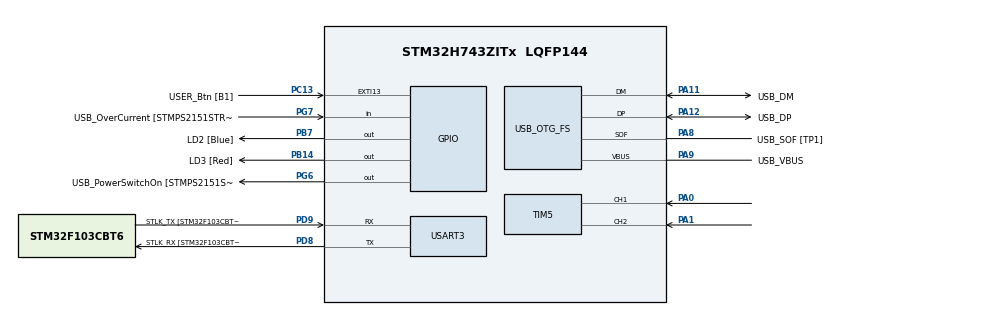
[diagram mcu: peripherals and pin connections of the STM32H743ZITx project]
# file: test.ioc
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Mcu.Family=STM32H7
Mcu.Name=STM32H743ZITx
Mcu.Package=LQFP144
NVIC.PriorityGroup=NVIC_PRIORITYGROUP_4
PA0.Signal=S_TIM5_CH1
PA1.Signal=S_TIM5_CH2
PA10.GPIO_Label=USB_ID
PA10.Signal=USB_OTG_FS_ID
PA11.GPIO_Label=USB_DM
PA11.Mode=Device_Only
PA11.Signal=USB_OTG_FS_DM
PA12.GPIO_Label=USB_DP
PA12.Mode=Device_Only
PA12.Signal=USB_OTG_FS_DP
PA2.GPIO_Label=RMII_MDIO
PA2.Signal=ETH_MDIO
PA7.GPIO_Label=RMII_CRS_DV
PA7.Signal=ETH_CRS_DV
PA8.GPIO_Label=USB_SOF [TP1]
PA8.Mode=Activate_SOF_FS
PA8.Signal=USB_OTG_FS_SOF
PA9.GPIO_Label=USB_VBUS
PA9.Mode=Activate_VBUS
PA9.Signal=USB_OTG_FS_VBUS
PB13.GPIO_Label=RMII_TXD1
PB13.Signal=ETH_TXD1
PB14.GPIO_Label=LD3 [Red]
PB14.Signal=GPIO_Output
PB7.GPIO_Label=LD2 [Blue]
PB7.Signal=GPIO_Output
PC1.GPIO_Label=RMII_MDC
PC1.Signal=ETH_MDC
PC13.GPIO_Label=USER_Btn [B1]
PC13.Signal=GPXTI13
PC14-OSC32_IN\ (OSC32_IN).Mode=LSE-External-Oscillator
PC14-OSC32_IN\ (OSC32_IN).Signal=RCC_OSC32_IN
PC15-OSC32_OUT\ (OSC32_OUT).Mode=LSE-External-Oscillator
PC15-OSC32_OUT\ (OSC32_OUT).Signal=RCC_OSC32_OUT
PC4.GPIO_Label=RMII_RXD0
PC4.Signal=ETH_RXD0
PC5.GPIO_Label=RMII_RXD1
PC5.Signal=ETH_RXD1
PD8.GPIO_Label=STLK_RX [STM32F103CBT6_PA3]
PD8.Mode=Asynchronous
PD8.Signal=USART3_TX
PD9.GPIO_Label=STLK_TX [STM32F103CBT6_PA2]
PD9.Mode=Asynchronous
PD9.Signal=USART3_RX
PG11.GPIO_Label=RMII_TX_EN
PG11.Signal=ETH_TX_EN
PG13.GPIO_Label=RMII_TXD0
PG13.Signal=ETH_TXD0
PG6.GPIO_Label=USB_PowerSwitchOn [STMPS2151STR_EN]
PG6.Signal=GPIO_Output
PG7.GPIO_Label=USB_OverCurrent [STMPS2151STR_FAULT]
PG7.Signal=GPIO_Input
PH0-OSC_IN\ (PH0).GPIO_Label=MCO
PH0-OSC_IN\ (PH0).Mode=HSE-External-Clock-Source
PH0-OSC_IN\ (PH0).Signal=RCC_OSC_IN
PH1-OSC_OUT\ (PH1).Signal=RCC_OSC_OUT
ProjectManager.HeapSize=0x200
ProjectManager.StackSize=0x400
ProjectManager.TargetToolchain=STM32CubeIDE
RCC.48MHZClocksFreq_Value=24000000
RCC.ADCFreq_Value=16125000
RCC.AHBFreq_Value=216000000
RCC.APB1CLKDivider=RCC_HCLK_DIV4
RCC.APB1Freq_Value=96000000
RCC.APB1TimFreq_Value=108000000
RCC.APB2CLKDivider=RCC_HCLK_DIV2
RCC.APB2Freq_Value=96000000
RCC.APB2TimFreq_Value=216000000
RCC.APB3Freq_Value=96000000
RCC.APB4Freq_Value=96000000
RCC.CortexFreq_Value=96000000
RCC.DIVM1=1
RCC.DIVN1=24
RCC.DIVQ1=4
RCC.HCLKFreq_Value=96000000
RCC.HSE_VALUE=8000000
RCC.HSI_VALUE=64000000
RCC.PLLM=25
RCC.PLLMUL=RCC_PLL_MUL9
RCC.PLLN=432
RCC.PLLQ=9
RCC.PRESCALERUSB=RCC_USBCLKSOURCE_PLL_DIV1_5
RCC.PWR_Regulator_Voltage_Scale=PWR_REGULATOR_VOLTAGE_SCALE1
RCC.SYSCLKFreq_VALUE=96000000
RCC.SYSCLKSource=RCC_SYSCLKSOURCE_PLLCLK
RCC.SYSCLKSourceVirtual=RCC_SYSCLKSOURCE_PLLCLK
RCC.USBFreq_Value=48000000
RCC.VCOOutputFreq_Value=432000000
SH.S_TIM5_CH1.0=TIM5_CH1,Encoder_Interface
SH.S_TIM5_CH2.0=TIM5_CH2,Encoder_Interface
TIM5.EncoderMode=TIM_ENCODERMODE_TI12
USART3.VirtualMode-Asynchronous=VM_ASYNC
USB_OTG_FS.VirtualMode=Device_Only
board=NUCLEO-H743ZI

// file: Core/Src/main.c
/* USER CODE BEGIN Header */
/**
  ******************************************************************************
  * @file           : main.c
  * @brief          : Main program body
  ******************************************************************************
  * @attention
  *
  * Copyright (c) 2022 STMicroelectronics.
  * All rights reserved.
  *
  * This software is licensed under terms that can be found in the LICENSE file
  * in the root directory of this software component.
  * If no LICENSE file comes with this software, it is provided AS-IS.
  *
  ******************************************************************************
  */
/* USER CODE END Header */
#include "main.h"

TIM_HandleTypeDef htim5;

UART_HandleTypeDef huart3;

PCD_HandleTypeDef hpcd_USB_OTG_FS;

/* USER CODE BEGIN PV */
uint32_t a = 0;
uint16_t b = 0;
/* USER CODE END PV */

void SystemClock_Config(void);
static void MX_GPIO_Init(void);
static void MX_USART3_UART_Init(void);
static void MX_USB_OTG_FS_PCD_Init(void);
static void MX_TIM5_Init(void);

int main(void)
{

  /* MCU Configuration--------------------------------------------------------*/

  /* Reset of all peripherals, Initializes the Flash interface and the Systick. */
  HAL_Init();

  /* Configure the system clock */
  SystemClock_Config();

  /* Initialize all configured peripherals */
  MX_GPIO_Init();
  MX_USART3_UART_Init();
  MX_USB_OTG_FS_PCD_Init();
  MX_TIM5_Init();

  /* Infinite loop */
  while (1)
  {

    /* USER CODE BEGIN 3 */
	  a = htim5.Instance->CNT;

  }
  /* USER CODE END 3 */
}

void SystemClock_Config(void)
{
  RCC_OscInitTypeDef RCC_OscInitStruct = {0};
  RCC_ClkInitTypeDef RCC_ClkInitStruct = {0};

  /** Supply configuration update enable
  */
  HAL_PWREx_ConfigSupply(PWR_LDO_SUPPLY);
  /** Configure the main internal regulator output voltage
  */
  __HAL_PWR_VOLTAGESCALING_CONFIG(PWR_REGULATOR_VOLTAGE_SCALE1);

  while(!__HAL_PWR_GET_FLAG(PWR_FLAG_VOSRDY)) {}
  /** Initializes the RCC Oscillators according to the specified parameters
  * in the RCC_OscInitTypeDef structure.
  */
  RCC_OscInitStruct.OscillatorType = RCC_OSCILLATORTYPE_HSE;
  RCC_OscInitStruct.HSEState = RCC_HSE_BYPASS;
  RCC_OscInitStruct.PLL.PLLState = RCC_PLL_ON;
  RCC_OscInitStruct.PLL.PLLSource = RCC_PLLSOURCE_HSE;
  RCC_OscInitStruct.PLL.PLLM = 1;
  RCC_OscInitStruct.PLL.PLLN = 24;
  RCC_OscInitStruct.PLL.PLLP = 2;
  RCC_OscInitStruct.PLL.PLLQ = 4;
  RCC_OscInitStruct.PLL.PLLR = 2;
  RCC_OscInitStruct.PLL.PLLRGE = RCC_PLL1VCIRANGE_3;
  RCC_OscInitStruct.PLL.PLLVCOSEL = RCC_PLL1VCOWIDE;
  RCC_OscInitStruct.PLL.PLLFRACN = 0;
  if (HAL_RCC_OscConfig(&RCC_OscInitStruct) != HAL_OK)
  {
    Error_Handler();
  }
  /** Initializes the CPU, AHB and APB buses clocks
  */
  RCC_ClkInitStruct.ClockType = RCC_CLOCKTYPE_HCLK|RCC_CLOCKTYPE_SYSCLK
                              |RCC_CLOCKTYPE_PCLK1|RCC_CLOCKTYPE_PCLK2
                              |RCC_CLOCKTYPE_D3PCLK1|RCC_CLOCKTYPE_D1PCLK1;
  RCC_ClkInitStruct.SYSCLKSource = RCC_SYSCLKSOURCE_PLLCLK;
  RCC_ClkInitStruct.SYSCLKDivider = RCC_SYSCLK_DIV1;
  RCC_ClkInitStruct.AHBCLKDivider = RCC_HCLK_DIV1;
  RCC_ClkInitStruct.APB3CLKDivider = RCC_APB3_DIV1;
  RCC_ClkInitStruct.APB1CLKDivider = RCC_APB1_DIV1;
  RCC_ClkInitStruct.APB2CLKDivider = RCC_APB2_DIV1;
  RCC_ClkInitStruct.APB4CLKDivider = RCC_APB4_DIV1;

  if (HAL_RCC_ClockConfig(&RCC_ClkInitStruct, FLASH_LATENCY_1) != HAL_OK)
  {
    Error_Handler();
  }
}

static void MX_TIM5_Init(void)
{

  TIM_Encoder_InitTypeDef sConfig = {0};
  TIM_MasterConfigTypeDef sMasterConfig = {0};

  htim5.Instance = TIM5;
  htim5.Init.Prescaler = 0;
  htim5.Init.CounterMode = TIM_COUNTERMODE_UP;
  htim5.Init.Period = 4294967295;
  htim5.Init.ClockDivision = TIM_CLOCKDIVISION_DIV1;
  htim5.Init.AutoReloadPreload = TIM_AUTORELOAD_PRELOAD_DISABLE;
  sConfig.EncoderMode = TIM_ENCODERMODE_TI12;
  sConfig.IC1Polarity = TIM_ICPOLARITY_RISING;
  sConfig.IC1Selection = TIM_ICSELECTION_DIRECTTI;
  sConfig.IC1Prescaler = TIM_ICPSC_DIV1;
  sConfig.IC1Filter = 0;
  sConfig.IC2Polarity = TIM_ICPOLARITY_RISING;
  sConfig.IC2Selection = TIM_ICSELECTION_DIRECTTI;
  sConfig.IC2Prescaler = TIM_ICPSC_DIV1;
  sConfig.IC2Filter = 0;
  if (HAL_TIM_Encoder_Init(&htim5, &sConfig) != HAL_OK)
  {
    Error_Handler();
  }
  sMasterConfig.MasterOutputTrigger = TIM_TRGO_RESET;
  sMasterConfig.MasterSlaveMode = TIM_MASTERSLAVEMODE_DISABLE;
  if (HAL_TIMEx_MasterConfigSynchronization(&htim5, &sMasterConfig) != HAL_OK)
  {
    Error_Handler();
  }

}

static void MX_USART3_UART_Init(void)
{

  huart3.Instance = USART3;
  huart3.Init.BaudRate = 115200;
  huart3.Init.WordLength = UART_WORDLENGTH_8B;
  huart3.Init.StopBits = UART_STOPBITS_1;
  huart3.Init.Parity = UART_PARITY_NONE;
  huart3.Init.Mode = UART_MODE_TX_RX;
  huart3.Init.HwFlowCtl = UART_HWCONTROL_NONE;
  huart3.Init.OverSampling = UART_OVERSAMPLING_16;
  huart3.Init.OneBitSampling = UART_ONE_BIT_SAMPLE_DISABLE;
  huart3.Init.ClockPrescaler = UART_PRESCALER_DIV1;
  huart3.AdvancedInit.AdvFeatureInit = UART_ADVFEATURE_NO_INIT;
  if (HAL_UART_Init(&huart3) != HAL_OK)
  {
    Error_Handler();
  }
  if (HAL_UARTEx_SetTxFifoThreshold(&huart3, UART_TXFIFO_THRESHOLD_1_8) != HAL_OK)
  {
    Error_Handler();
  }
  if (HAL_UARTEx_SetRxFifoThreshold(&huart3, UART_RXFIFO_THRESHOLD_1_8) != HAL_OK)
  {
    Error_Handler();
  }
  if (HAL_UARTEx_DisableFifoMode(&huart3) != HAL_OK)
  {
    Error_Handler();
  }

}

static void MX_USB_OTG_FS_PCD_Init(void)
{

  hpcd_USB_OTG_FS.Instance = USB_OTG_FS;
  hpcd_USB_OTG_FS.Init.dev_endpoints = 9;
  hpcd_USB_OTG_FS.Init.speed = PCD_SPEED_FULL;
  hpcd_USB_OTG_FS.Init.dma_enable = DISABLE;
  hpcd_USB_OTG_FS.Init.phy_itface = PCD_PHY_EMBEDDED;
  hpcd_USB_OTG_FS.Init.Sof_enable = ENABLE;
  hpcd_USB_OTG_FS.Init.low_power_enable = DISABLE;
  hpcd_USB_OTG_FS.Init.lpm_enable = DISABLE;
  hpcd_USB_OTG_FS.Init.battery_charging_enable = ENABLE;
  hpcd_USB_OTG_FS.Init.vbus_sensing_enable = ENABLE;
  hpcd_USB_OTG_FS.Init.use_dedicated_ep1 = DISABLE;
  if (HAL_PCD_Init(&hpcd_USB_OTG_FS) != HAL_OK)
  {
    Error_Handler();
  }

}

static void MX_GPIO_Init(void)
{
  GPIO_InitTypeDef GPIO_InitStruct = {0};

  /* GPIO Ports Clock Enable */
  __HAL_RCC_GPIOC_CLK_ENABLE();
  __HAL_RCC_GPIOH_CLK_ENABLE();
  __HAL_RCC_GPIOA_CLK_ENABLE();
  __HAL_RCC_GPIOB_CLK_ENABLE();
  __HAL_RCC_GPIOD_CLK_ENABLE();
  __HAL_RCC_GPIOG_CLK_ENABLE();

  /*Configure GPIO pin Output Level */
  HAL_GPIO_WritePin(GPIOB, LD3_Pin|LD2_Pin, GPIO_PIN_RESET);

  /*Configure GPIO pin Output Level */
  HAL_GPIO_WritePin(USB_PowerSwitchOn_GPIO_Port, USB_PowerSwitchOn_Pin, GPIO_PIN_RESET);

  /*Configure GPIO pin : USER_Btn_Pin */
  GPIO_InitStruct.Pin = USER_Btn_Pin;
  GPIO_InitStruct.Mode = GPIO_MODE_IT_RISING;
  GPIO_InitStruct.Pull = GPIO_NOPULL;
  HAL_GPIO_Init(USER_Btn_GPIO_Port, &GPIO_InitStruct);

  /*Configure GPIO pins : RMII_MDC_Pin RMII_RXD0_Pin RMII_RXD1_Pin */
  GPIO_InitStruct.Pin = RMII_MDC_Pin|RMII_RXD0_Pin|RMII_RXD1_Pin;
  GPIO_InitStruct.Mode = GPIO_MODE_AF_PP;
  GPIO_InitStruct.Pull = GPIO_NOPULL;
  GPIO_InitStruct.Speed = GPIO_SPEED_FREQ_LOW;
  GPIO_InitStruct.Alternate = GPIO_AF11_ETH;
  HAL_GPIO_Init(GPIOC, &GPIO_InitStruct);

  /*Configure GPIO pins : RMII_MDIO_Pin RMII_CRS_DV_Pin */
  GPIO_InitStruct.Pin = RMII_MDIO_Pin|RMII_CRS_DV_Pin;
  GPIO_InitStruct.Mode = GPIO_MODE_AF_PP;
  GPIO_InitStruct.Pull = GPIO_NOPULL;
  GPIO_InitStruct.Speed = GPIO_SPEED_FREQ_LOW;
  GPIO_InitStruct.Alternate = GPIO_AF11_ETH;
  HAL_GPIO_Init(GPIOA, &GPIO_InitStruct);

  /*Configure GPIO pin : RMII_TXD1_Pin */
  GPIO_InitStruct.Pin = RMII_TXD1_Pin;
  GPIO_InitStruct.Mode = GPIO_MODE_AF_PP;
  GPIO_InitStruct.Pull = GPIO_NOPULL;
  GPIO_InitStruct.Speed = GPIO_SPEED_FREQ_LOW;
  GPIO_InitStruct.Alternate = GPIO_AF11_ETH;
  HAL_GPIO_Init(RMII_TXD1_GPIO_Port, &GPIO_InitStruct);

  /*Configure GPIO pins : LD3_Pin LD2_Pin */
  GPIO_InitStruct.Pin = LD3_Pin|LD2_Pin;
  GPIO_InitStruct.Mode = GPIO_MODE_OUTPUT_PP;
  GPIO_InitStruct.Pull = GPIO_NOPULL;
  GPIO_InitStruct.Speed = GPIO_SPEED_FREQ_LOW;
  HAL_GPIO_Init(GPIOB, &GPIO_InitStruct);

  /*Configure GPIO pin : USB_PowerSwitchOn_Pin */
  GPIO_InitStruct.Pin = USB_PowerSwitchOn_Pin;
  GPIO_InitStruct.Mode = GPIO_MODE_OUTPUT_PP;
  GPIO_InitStruct.Pull = GPIO_NOPULL;
  GPIO_InitStruct.Speed = GPIO_SPEED_FREQ_LOW;
  HAL_GPIO_Init(USB_PowerSwitchOn_GPIO_Port, &GPIO_InitStruct);

  /*Configure GPIO pin : USB_OverCurrent_Pin */
  GPIO_InitStruct.Pin = USB_OverCurrent_Pin;
  GPIO_InitStruct.Mode = GPIO_MODE_INPUT;
  GPIO_InitStruct.Pull = GPIO_NOPULL;
  HAL_GPIO_Init(USB_OverCurrent_GPIO_Port, &GPIO_InitStruct);

  /*Configure GPIO pins : RMII_TX_EN_Pin RMII_TXD0_Pin */
  GPIO_InitStruct.Pin = RMII_TX_EN_Pin|RMII_TXD0_Pin;
  GPIO_InitStruct.Mode = GPIO_MODE_AF_PP;
  GPIO_InitStruct.Pull = GPIO_NOPULL;
  GPIO_InitStruct.Speed = GPIO_SPEED_FREQ_LOW;
  GPIO_InitStruct.Alternate = GPIO_AF11_ETH;
  HAL_GPIO_Init(GPIOG, &GPIO_InitStruct);

}

void Error_Handler(void)
{
  __disable_irq();
  while (1)
  {
  }
}
